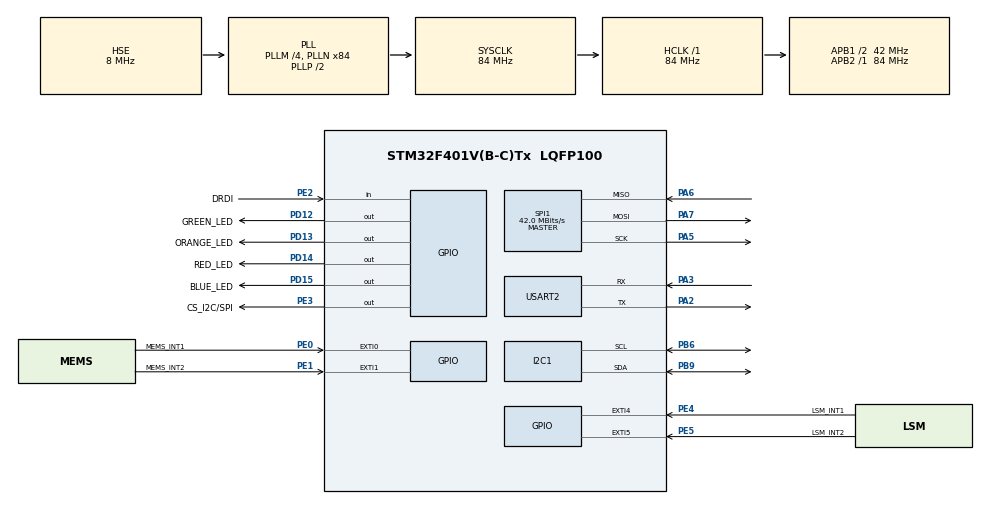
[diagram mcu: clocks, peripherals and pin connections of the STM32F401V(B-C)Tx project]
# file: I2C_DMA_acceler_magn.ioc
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Dma.Request0=USART2_TX
Dma.USART2_TX.0.Channel=DMA_CHANNEL_4
Dma.USART2_TX.0.Direction=DMA_MEMORY_TO_PERIPH
Dma.USART2_TX.0.FIFOMode=DMA_FIFOMODE_DISABLE
Dma.USART2_TX.0.Instance=DMA1_Stream6
Dma.USART2_TX.0.MemDataAlignment=DMA_MDATAALIGN_WORD
Dma.USART2_TX.0.MemInc=DMA_MINC_ENABLE
Dma.USART2_TX.0.Mode=DMA_NORMAL
Dma.USART2_TX.0.PeriphDataAlignment=DMA_PDATAALIGN_WORD
Dma.USART2_TX.0.PeriphInc=DMA_PINC_DISABLE
Dma.USART2_TX.0.Priority=DMA_PRIORITY_LOW
Mcu.Family=STM32F4
Mcu.Name=STM32F401V(B-C)Tx
Mcu.Package=LQFP100
NVIC.DMA1_Stream6_IRQn=true\:0\:0\:false
NVIC.PriorityGroup=NVIC_PRIORITYGROUP_4
PA2.Mode=Asynchronous
PA2.Signal=USART2_TX
PA3.Mode=Asynchronous
PA3.Signal=USART2_RX
PA5.Mode=Full_Duplex_Master
PA5.Signal=SPI1_SCK
PA6.Mode=Full_Duplex_Master
PA6.Signal=SPI1_MISO
PA7.Mode=Full_Duplex_Master
PA7.Signal=SPI1_MOSI
PB6.Mode=I2C
PB6.Signal=I2C1_SCL
PB9.Mode=I2C
PB9.Signal=I2C1_SDA
PD12.GPIO_Label=GREEN_LED
PD12.Signal=GPIO_Output
PD13.GPIO_Label=ORANGE_LED
PD13.Signal=GPIO_Output
PD14.GPIO_Label=RED_LED
PD14.Signal=GPIO_Output
PD15.GPIO_Label=BLUE_LED
PD15.Signal=GPIO_Output
PE0.GPIO_Label=MEMS_INT1
PE0.Signal=GPXTI0
PE1.GPIO_Label=MEMS_INT2
PE1.Signal=GPXTI1
PE2.GPIO_Label=DRDI
PE2.Signal=GPIO_Input
PE3.GPIO_Label=CS_I2C/SPI
PE3.Signal=GPIO_Output
PE4.GPIO_Label=LSM_INT1
PE4.Signal=GPXTI4
PE5.GPIO_Label=LSM_INT2
PE5.Signal=GPXTI5
PH0\ -\ OSC_IN.Mode=HSE-External-Oscillator
PH0\ -\ OSC_IN.Signal=RCC_OSC_IN
PH1\ -\ OSC_OUT.Mode=HSE-External-Oscillator
PH1\ -\ OSC_OUT.Signal=RCC_OSC_OUT
ProjectManager.TargetToolchain=SW4STM32
RCC.48MHZClocksFreq_Value=42000000
RCC.AHBFreq_Value=84000000
RCC.APB1CLKDivider=RCC_HCLK_DIV2
RCC.APB1Freq_Value=42000000
RCC.APB1TimCLKDivider=1
RCC.APB1TimFreq_Value=42000000
RCC.APB2Freq_Value=84000000
RCC.APB2TimFreq_Value=84000000
RCC.CortexFreq_Value=84000000
RCC.HCLKFreq_Value=84000000
RCC.HSE_VALUE=8000000
RCC.HSI_VALUE=16000000
RCC.LSE_VALUE=32768
RCC.PLLM=4
RCC.PLLN=84
RCC.PLLSourceVirtual=RCC_PLLSOURCE_HSE
RCC.SYSCLKFreq_VALUE=84000000
RCC.SYSCLKSource=RCC_SYSCLKSOURCE_PLLCLK
RCC.VCOOutputFreq_Value=168000000
SPI1.CalculateBaudRate=42.0 MBits/s
SPI1.Mode=SPI_MODE_MASTER
VP_TIM1_VS_ClockSourceINT.Mode=Internal
board=I2C_DMA_acceler_magn

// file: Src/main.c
/**
  ******************************************************************************
  * File Name          : main.c
  * Description        : Main program body
  ******************************************************************************
  *
  * COPYRIGHT(c) 2016 STMicroelectronics
  *
  * Redistribution and use in source and binary forms, with or without modification,
  * are permitted provided that the following conditions are met:
  *   1. Redistributions of source code must retain the above copyright notice,
  *      this list of conditions and the following disclaimer.
  *   2. Redistributions in binary form must reproduce the above copyright notice,
  *      this list of conditions and the following disclaimer in the documentation
  *      and/or other materials provided with the distribution.
  *   3. Neither the name of STMicroelectronics nor the names of its contributors
  *      may be used to endorse or promote products derived from this software
  *      without specific prior written permission.
  *
  * THIS SOFTWARE IS PROVIDED BY THE COPYRIGHT HOLDERS AND CONTRIBUTORS "AS IS"
  * AND ANY EXPRESS OR IMPLIED WARRANTIES, INCLUDING, BUT NOT LIMITED TO, THE
  * IMPLIED WARRANTIES OF MERCHANTABILITY AND FITNESS FOR A PARTICULAR PURPOSE ARE
  * DISCLAIMED. IN NO EVENT SHALL THE COPYRIGHT HOLDER OR CONTRIBUTORS BE LIABLE
  * FOR ANY DIRECT, INDIRECT, INCIDENTAL, SPECIAL, EXEMPLARY, OR CONSEQUENTIAL
  * DAMAGES (INCLUDING, BUT NOT LIMITED TO, PROCUREMENT OF SUBSTITUTE GOODS OR
  * SERVICES; LOSS OF USE, DATA, OR PROFITS; OR BUSINESS INTERRUPTION) HOWEVER
  * CAUSED AND ON ANY THEORY OF LIABILITY, WHETHER IN CONTRACT, STRICT LIABILITY,
  * OR TORT (INCLUDING NEGLIGENCE OR OTHERWISE) ARISING IN ANY WAY OUT OF THE USE
  * OF THIS SOFTWARE, EVEN IF ADVISED OF THE POSSIBILITY OF SUCH DAMAGE.
  *
  ******************************************************************************
  */
#include "stm32f4xx_hal.h"

/* USER CODE BEGIN Includes */
#include "timer.h"
#include "system.h"
#include "l2c.h"
/* USER CODE END Includes */

I2C_HandleTypeDef hi2c1;

SPI_HandleTypeDef hspi1;

TIM_HandleTypeDef htim1;

UART_HandleTypeDef huart2;
DMA_HandleTypeDef hdma_usart2_tx;

/* USER CODE BEGIN PV */
/* Private variables ---------------------------------------------------------*/

/* USER CODE END PV */

void SystemClock_Config(void);
static void MX_GPIO_Init(void);
static void MX_DMA_Init(void);
static void MX_I2C1_Init(void);
static void MX_SPI1_Init(void);
static void MX_TIM1_Init(void);
static void MX_USART2_UART_Init(void);

/* USER CODE BEGIN PFP */
/* Private function prototypes -----------------------------------------------*/

/* USER CODE END PFP */

int main(void)
{

  /* MCU Configuration----------------------------------------------------------*/

  /* Reset of all peripherals, Initializes the Flash interface and the Systick. */
  HAL_Init();

  /* Configure the system clock */
  SystemClock_Config();

  /* Initialize all configured peripherals */
  MX_GPIO_Init();
  MX_DMA_Init();
  MX_I2C1_Init();
  MX_SPI1_Init();
  MX_TIM1_Init();
  MX_USART2_UART_Init();

  /* USER CODE BEGIN 2 */

  //startTimer1();

	startAndCheckAccelerometr();

  /* USER CODE END 2 */

  /* Infinite loop */
  while (1)
  {

  /* USER CODE BEGIN 3 */

#ifdef MODE_1
	  update_LEDS_ByAccelerometr();
#endif

	}
  /* USER CODE END 3 */

}

/** System Clock Configuration
*/
void SystemClock_Config(void)
{

  RCC_OscInitTypeDef RCC_OscInitStruct;
  RCC_ClkInitTypeDef RCC_ClkInitStruct;

  __PWR_CLK_ENABLE();

  __HAL_PWR_VOLTAGESCALING_CONFIG(PWR_REGULATOR_VOLTAGE_SCALE2);

  RCC_OscInitStruct.OscillatorType = RCC_OSCILLATORTYPE_HSE;
  RCC_OscInitStruct.HSEState = RCC_HSE_ON;
  RCC_OscInitStruct.PLL.PLLState = RCC_PLL_ON;
  RCC_OscInitStruct.PLL.PLLSource = RCC_PLLSOURCE_HSE;
  RCC_OscInitStruct.PLL.PLLM = 4;
  RCC_OscInitStruct.PLL.PLLN = 84;
  RCC_OscInitStruct.PLL.PLLP = RCC_PLLP_DIV2;
  RCC_OscInitStruct.PLL.PLLQ = 4;
  HAL_RCC_OscConfig(&RCC_OscInitStruct);

  RCC_ClkInitStruct.ClockType = RCC_CLOCKTYPE_SYSCLK|RCC_CLOCKTYPE_PCLK1;
  RCC_ClkInitStruct.SYSCLKSource = RCC_SYSCLKSOURCE_PLLCLK;
  RCC_ClkInitStruct.AHBCLKDivider = RCC_SYSCLK_DIV1;
  RCC_ClkInitStruct.APB1CLKDivider = RCC_HCLK_DIV2;
  RCC_ClkInitStruct.APB2CLKDivider = RCC_HCLK_DIV1;
  HAL_RCC_ClockConfig(&RCC_ClkInitStruct, FLASH_LATENCY_2);

  HAL_SYSTICK_Config(HAL_RCC_GetHCLKFreq()/1000);

  HAL_SYSTICK_CLKSourceConfig(SYSTICK_CLKSOURCE_HCLK);

  /* SysTick_IRQn interrupt configuration */
  HAL_NVIC_SetPriority(SysTick_IRQn, 0, 0);
}

/* I2C1 init function */
void MX_I2C1_Init(void)
{

  hi2c1.Instance = I2C1;
  hi2c1.Init.ClockSpeed = 100000;
  hi2c1.Init.DutyCycle = I2C_DUTYCYCLE_2;
  hi2c1.Init.OwnAddress1 = 0;
  hi2c1.Init.AddressingMode = I2C_ADDRESSINGMODE_7BIT;
  hi2c1.Init.DualAddressMode = I2C_DUALADDRESS_DISABLED;
  hi2c1.Init.OwnAddress2 = 0;
  hi2c1.Init.GeneralCallMode = I2C_GENERALCALL_DISABLED;
  hi2c1.Init.NoStretchMode = I2C_NOSTRETCH_DISABLED;
  HAL_I2C_Init(&hi2c1);

}

/* SPI1 init function */
void MX_SPI1_Init(void)
{

  hspi1.Instance = SPI1;
  hspi1.Init.Mode = SPI_MODE_MASTER;
  hspi1.Init.Direction = SPI_DIRECTION_2LINES;
  hspi1.Init.DataSize = SPI_DATASIZE_8BIT;
  hspi1.Init.CLKPolarity = SPI_POLARITY_LOW;
  hspi1.Init.CLKPhase = SPI_PHASE_1EDGE;
  hspi1.Init.NSS = SPI_NSS_SOFT;
  hspi1.Init.BaudRatePrescaler = SPI_BAUDRATEPRESCALER_2;
  hspi1.Init.FirstBit = SPI_FIRSTBIT_MSB;
  hspi1.Init.TIMode = SPI_TIMODE_DISABLED;
  hspi1.Init.CRCCalculation = SPI_CRCCALCULATION_DISABLED;
  hspi1.Init.CRCPolynomial = 10;
  HAL_SPI_Init(&hspi1);

}

/* TIM1 init function */
void MX_TIM1_Init(void)
{

  TIM_ClockConfigTypeDef sClockSourceConfig;
  TIM_MasterConfigTypeDef sMasterConfig;

  htim1.Instance = TIM1;
  htim1.Init.Prescaler = 0;
  htim1.Init.CounterMode = TIM_COUNTERMODE_UP;
  htim1.Init.Period = 0;
  htim1.Init.ClockDivision = TIM_CLOCKDIVISION_DIV1;
  htim1.Init.RepetitionCounter = 0;
  HAL_TIM_Base_Init(&htim1);

  sClockSourceConfig.ClockSource = TIM_CLOCKSOURCE_INTERNAL;
  HAL_TIM_ConfigClockSource(&htim1, &sClockSourceConfig);

  sMasterConfig.MasterOutputTrigger = TIM_TRGO_RESET;
  sMasterConfig.MasterSlaveMode = TIM_MASTERSLAVEMODE_DISABLE;
  HAL_TIMEx_MasterConfigSynchronization(&htim1, &sMasterConfig);

}

/* USART2 init function */
void MX_USART2_UART_Init(void)
{

  huart2.Instance = USART2;
  huart2.Init.BaudRate = 115200;
  huart2.Init.WordLength = UART_WORDLENGTH_8B;
  huart2.Init.StopBits = UART_STOPBITS_1;
  huart2.Init.Parity = UART_PARITY_NONE;
  huart2.Init.Mode = UART_MODE_TX_RX;
  huart2.Init.HwFlowCtl = UART_HWCONTROL_NONE;
  huart2.Init.OverSampling = UART_OVERSAMPLING_16;
  HAL_UART_Init(&huart2);

}

void MX_DMA_Init(void)
{
  /* DMA controller clock enable */
  __DMA1_CLK_ENABLE();

  /* DMA interrupt init */
  HAL_NVIC_SetPriority(DMA1_Stream6_IRQn, 0, 0);
  HAL_NVIC_EnableIRQ(DMA1_Stream6_IRQn);

}

/** Configure pins as
        * Analog
        * Input
        * Output
        * EVENT_OUT
        * EXTI
*/
void MX_GPIO_Init(void)
{

  GPIO_InitTypeDef GPIO_InitStruct;

  /* GPIO Ports Clock Enable */
  __GPIOE_CLK_ENABLE();
  __GPIOH_CLK_ENABLE();
  __GPIOA_CLK_ENABLE();
  __GPIOD_CLK_ENABLE();
  __GPIOB_CLK_ENABLE();

  /*Configure GPIO pin : DRDI_Pin */
  GPIO_InitStruct.Pin = DRDI_Pin;
  GPIO_InitStruct.Mode = GPIO_MODE_INPUT;
  GPIO_InitStruct.Pull = GPIO_NOPULL;
  HAL_GPIO_Init(DRDI_GPIO_Port, &GPIO_InitStruct);

  /*Configure GPIO pin : CS_I2C_SPI_Pin */
  GPIO_InitStruct.Pin = CS_I2C_SPI_Pin;
  GPIO_InitStruct.Mode = GPIO_MODE_OUTPUT_PP;
  GPIO_InitStruct.Pull = GPIO_NOPULL;
  GPIO_InitStruct.Speed = GPIO_SPEED_LOW;
  HAL_GPIO_Init(CS_I2C_SPI_GPIO_Port, &GPIO_InitStruct);

  /*Configure GPIO pins : LSM_INT1_Pin LSM_INT2_Pin MEMS_INT1_Pin MEMS_INT2_Pin */
  GPIO_InitStruct.Pin = LSM_INT1_Pin|LSM_INT2_Pin|MEMS_INT1_Pin|MEMS_INT2_Pin;
  GPIO_InitStruct.Mode = GPIO_MODE_IT_RISING;
  GPIO_InitStruct.Pull = GPIO_NOPULL;
  HAL_GPIO_Init(GPIOE, &GPIO_InitStruct);

  /*Configure GPIO pins : GREEN_LED_Pin ORANGE_LED_Pin RED_LED_Pin BLUE_LED_Pin */
  GPIO_InitStruct.Pin = GREEN_LED_Pin|ORANGE_LED_Pin|RED_LED_Pin|BLUE_LED_Pin;
  GPIO_InitStruct.Mode = GPIO_MODE_OUTPUT_PP;
  GPIO_InitStruct.Pull = GPIO_NOPULL;
  GPIO_InitStruct.Speed = GPIO_SPEED_LOW;
  HAL_GPIO_Init(GPIOD, &GPIO_InitStruct);

}

/************************ (C) COPYRIGHT STMicroelectronics *****END OF FILE****/
